# STM32F733xx register map
File version: 1.0
Registers are 32-bit, read-write, reset 0x0 unless marked. A register's access mark holds for its fields unless they carry their own. Offsets are from the block's base; [hi:lo] are bit positions; {n}, {i} and the like mark numbered series.

## USB_HS_PHYC — USB_HS_PHY_Registers
Base 0x40017C00
0x00 USB_HS_PHYC_PLL — This register is used to control the PLL of the HS PHY. 000h
0x0C USB_HS_PHYC_TUNE — This register is used to control the tuning interface of the High Speed PHY. 00Ch
0x18 USB_HS_PHYC_LDO — This register is used to control the regulator (LDO). 018h

## GPIOA — General Purpose I/O
Base 0x40020000
Same registers: GPIOB 0x40020400, GPIOC 0x40020800, GPIOD 0x40020C00, GPIOE 0x40021000, GPIOF 0x40021400, GPIOG 0x40021800, GPIOH 0x40021C00, GPIOI 0x40022000
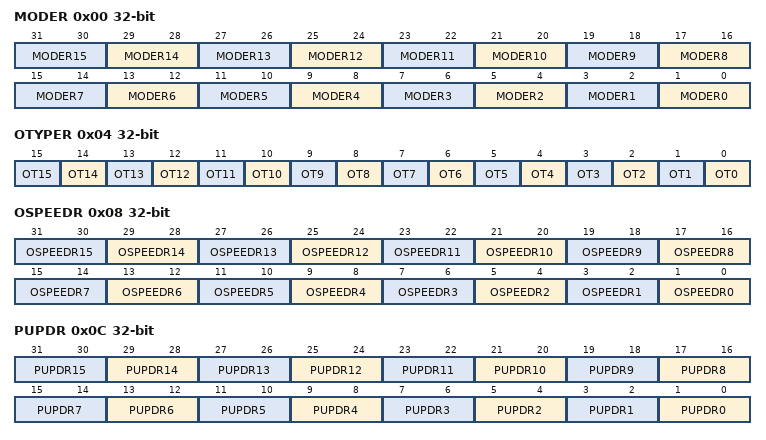
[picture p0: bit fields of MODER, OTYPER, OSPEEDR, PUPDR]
0x00 MODER — GPIO port mode register
  [2n+1:2n] MODER{n} (n=0..15)
0x04 OTYPER — GPIO port output type register
  [n] OT{n} (n=0..15)
0x08 OSPEEDR — GPIO port output speed register
  [2n+1:2n] OSPEEDR{n} (n=0..15)
0x0C PUPDR — GPIO port pull-up/pull-down register
  [2n+1:2n] PUPDR{n} (n=0..15)
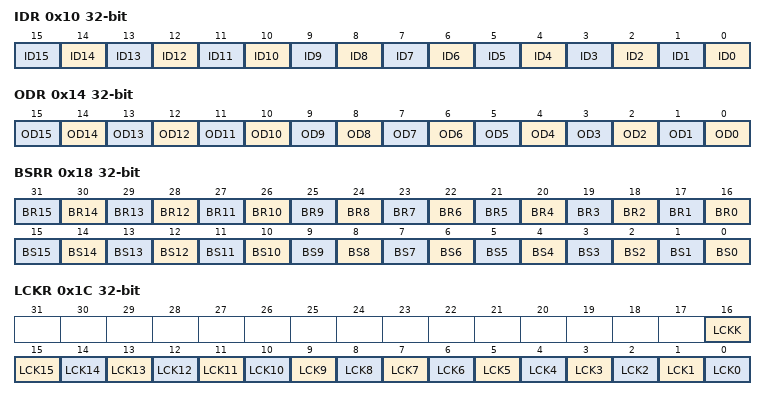
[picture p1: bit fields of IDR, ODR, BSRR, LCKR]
0x10 IDR — GPIO port input data register
  [n] ID{n} (n=0..15)
0x14 ODR — GPIO port output data register
  [n] OD{n} (n=0..15)
0x18 BSRR — GPIO port bit set/reset register
  [n+16] BR{n} (n=0..15), [n] BS{n} (n=0..15)
0x1C LCKR — GPIO port configuration lock register
  [16] LCKK, [n] LCK{n} (n=0..15)
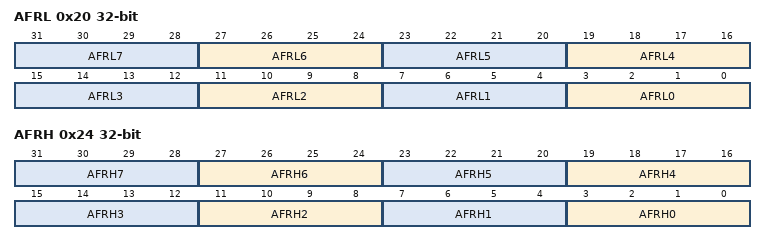
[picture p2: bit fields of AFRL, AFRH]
0x20 AFRL — GPIO alternate function registers
  [4n+3:4n] AFRL{n} (n=0..7)
0x24 AFRH — GPIO alternate function registers
  [4n+3:4n] AFRH{n} (n=0..7)

## CRC — CRC calculation unit
Base 0x40023000
0x00 DR — CRC Data register
  [31:0] DR — Data register bits
0x04 IDR 8-bit — CRC Independent data register
  [7:0] IDR — General-purpose 8-bit data register bits
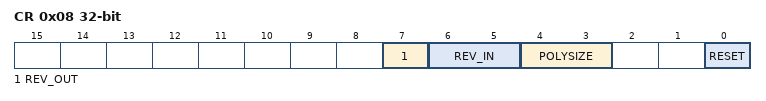
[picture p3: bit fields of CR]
0x08 CR — CRC Control register
  [7] REV_OUT — REV_OUT Reverse Output Data bits
    0=NONE (Output Data bit order not affected); 1=BIT (Output Data bit reversal done by bit)
  [6:5] REV_IN — REV_IN Reverse Input Data bits
    0=NONE (Input Data bit order not affected); 1=BYTE (Input Data bit reversal done by byte); 2=HALFWORD (Input Data bit reversal done by half-word); 3=WORD (Input Data bit reversal done by word)
  [4:3] POLYSIZE — Polynomial size bits
    0=POLYLENGTH_32B (32 bits Polynomial size); 1=POLYLENGTH_16B (16 bits Polynomial size); 2=POLYLENGTH_8B (8 bits Polynomial size); 3=POLYLENGTH_7B (7 bits Polynomial size)
  [0] RESET — RESET the CRC computation unit bit
0x10 INIT — Initial CRC value register
  [31:0] INIT — Initial CRC value bits
0x14 POL — CRC polynomial register
  [31:0] POL — Coefficients of the polynomial

## FLASH — FLASH Registers
Base 0x40023C00
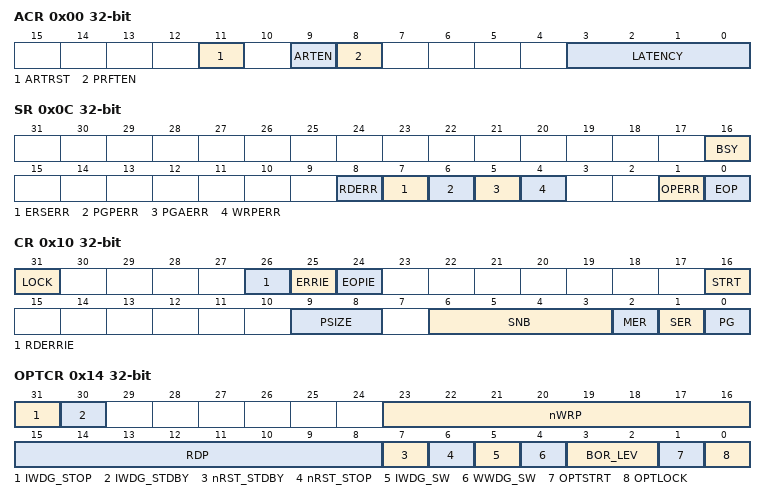
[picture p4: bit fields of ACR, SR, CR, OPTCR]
0x00 ACR — FLASH access control register
  [11] ARTRST
  [9] ARTEN
  [8] PRFTEN
  [3:0] LATENCY
    0=FLASH Zero wait state; 1=FLASH One wait state; 2=FLASH Two wait states; 3=FLASH Three wait states; 4=FLASH Four wait states; 5=FLASH five wait state; 6=FLASH six wait state; 7=FLASH seven wait states; 8=FLASH eight wait states; 9=FLASH nine wait states; 10=FLASH ten wait states; 11=FLASH eleven wait states; 12=FLASH twelve wait states; 13=FLASH thirteen wait states; 14=FLASH fourteen wait states; 15=FLASH fifteen wait states
0x04 KEYR — FLASH key register
0x08 OPTKEYR — FLASH option key register
0x0C SR — FLASH status register
  [16] BSY, [8] RDERR, [7] ERSERR, [6] PGPERR, [5] PGAERR, [4] WRPERR, [1] OPERR, [0] EOP
0x10 CR — FLASH control register
  [31] LOCK, [26] RDERRIE, [25] ERRIE, [24] EOPIE, [16] STRT, [9:8] PSIZE, [6:3] SNB, [2] MER, [1] SER, [0] PG
0x14 OPTCR — FLASH option control register
  [31] IWDG_STOP, [30] IWDG_STDBY, [23:16] nWRP, [15:8] RDP, [7] nRST_STDBY, [6] nRST_STOP, [5] IWDG_SW, [4] WWDG_SW, [3:2] BOR_LEV, [1] OPTSTRT, [0] OPTLOCK
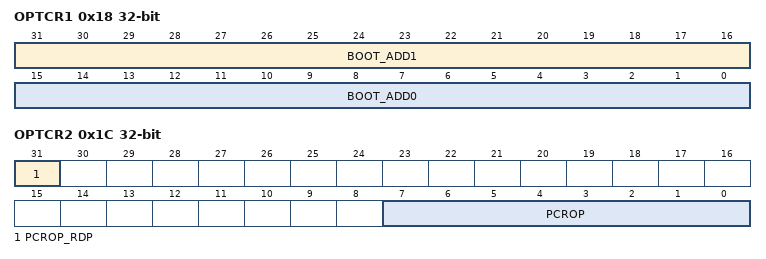
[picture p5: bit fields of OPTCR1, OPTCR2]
0x18 OPTCR1 — FLASH option control register 1
  [31:16] BOOT_ADD1, [15:0] BOOT_ADD0
0x1C OPTCR2 — FLASH option control register 2
  [31] PCROP_RDP, [7:0] PCROP

## DMA1
Base 0x40026000
Same registers: DMA2 0x40026400
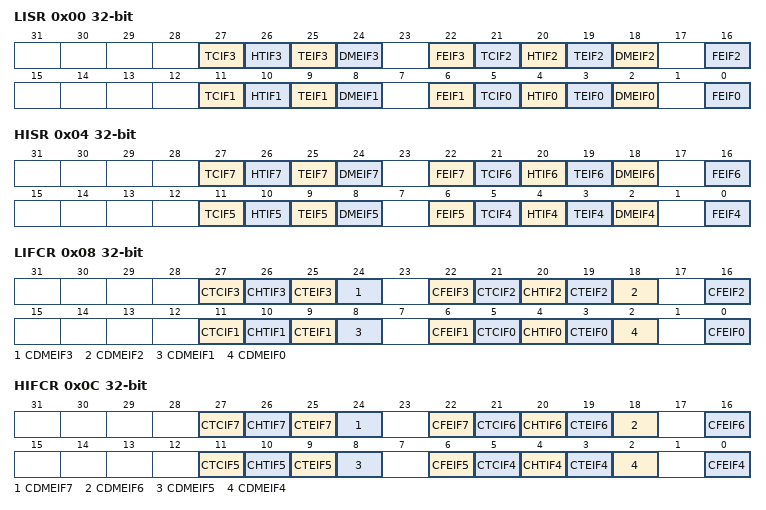
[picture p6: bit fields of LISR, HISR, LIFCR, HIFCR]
0x00 LISR — DMA low interrupt status register
  [27] TCIF3, [26] HTIF3, [25] TEIF3, [24] DMEIF3, [22] FEIF3, [21] TCIF2, [20] HTIF2, [19] TEIF2, [18] DMEIF2, [16] FEIF2, [11] TCIF1, [10] HTIF1, [9] TEIF1, [8] DMEIF1, [6] FEIF1, [5] TCIF0, [4] HTIF0, [3] TEIF0, [2] DMEIF0, [0] FEIF0
0x04 HISR — DMA high interrupt status register
  [27] TCIF7, [26] HTIF7, [25] TEIF7, [24] DMEIF7, [22] FEIF7, [21] TCIF6, [20] HTIF6, [19] TEIF6, [18] DMEIF6, [16] FEIF6, [11] TCIF5, [10] HTIF5, [9] TEIF5, [8] DMEIF5, [6] FEIF5, [5] TCIF4, [4] HTIF4, [3] TEIF4, [2] DMEIF4, [0] FEIF4
0x08 LIFCR — DMA low interrupt flag clear register
  [27] CTCIF3, [26] CHTIF3, [25] CTEIF3, [24] CDMEIF3, [22] CFEIF3, [21] CTCIF2, [20] CHTIF2, [19] CTEIF2, [18] CDMEIF2, [16] CFEIF2, [11] CTCIF1, [10] CHTIF1, [9] CTEIF1, [8] CDMEIF1, [6] CFEIF1, [5] CTCIF0, [4] CHTIF0, [3] CTEIF0, [2] CDMEIF0, [0] CFEIF0
0x0C HIFCR — DMA high interrupt flag clear register
  [27] CTCIF7, [26] CHTIF7, [25] CTEIF7, [24] CDMEIF7, [22] CFEIF7, [21] CTCIF6, [20] CHTIF6, [19] CTEIF6, [18] CDMEIF6, [16] CFEIF6, [11] CTCIF5, [10] CHTIF5, [9] CTEIF5, [8] CDMEIF5, [6] CFEIF5, [5] CTCIF4, [4] CHTIF4, [3] CTEIF4, [2] CDMEIF4, [0] CFEIF4
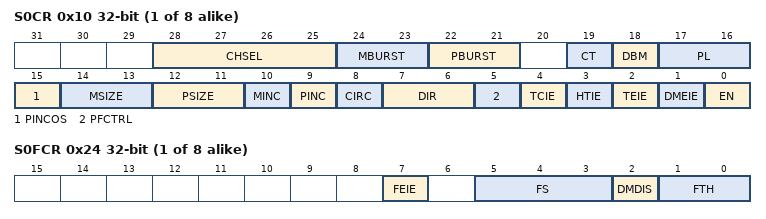
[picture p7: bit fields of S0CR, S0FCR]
{0x10+0x18*i} S{i}CR (i=0..7) — DMA stream x configuration register
  [28:25] CHSEL, [24:23] MBURST, [22:21] PBURST, [19] CT, [18] DBM, [17:16] PL, [15] PINCOS, [14:13] MSIZE, [12:11] PSIZE, [10] MINC, [9] PINC, [8] CIRC, [7:6] DIR, [5] PFCTRL, [4] TCIE, [3] HTIE, [2] TEIE, [1] DMEIE, [0] EN
{0x14+0x18*i} S{i}NDTR (i=0..7) — DMA stream x number of data register
  [15:0] SxNDT
{0x18+0x18*i} S{i}PAR (i=0..7) — DMA stream x peripheral address register
  [31:0] PA — Peripheral Address
{0x1C+0x18*i} S{i}M0AR (i=0..7) — DMA stream x memory 0 address register
  [31:0] M0A — Memory Address
{0x20+0x18*i} S{i}M1AR (i=0..7) — DMA stream x memory 1 address register
  [31:0] M1A — Memory Address
{0x24+0x18*i} S{i}FCR (i=0..7) — DMA stream x FIFO control register
  [7] FEIE, [5:3] FS, [2] DMDIS, [1:0] FTH
